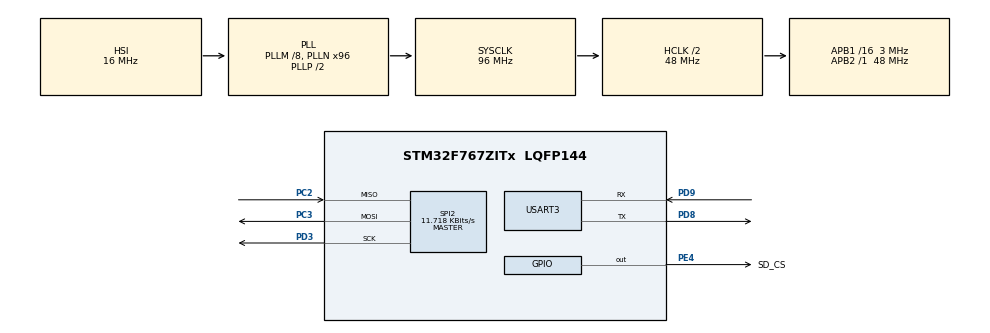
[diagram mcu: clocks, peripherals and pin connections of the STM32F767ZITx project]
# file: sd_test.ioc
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FATFS._FS_NORTC=0
FATFS._MAX_SS=512
FATFS._USE_LFN=0
Mcu.Family=STM32F7
Mcu.Name=STM32F767ZITx
Mcu.Package=LQFP144
NVIC.PriorityGroup=NVIC_PRIORITYGROUP_4
PA13.Mode=Serial_Wire
PA13.Signal=SYS_JTMS-SWDIO
PA14.Mode=Serial_Wire
PA14.Signal=SYS_JTCK-SWCLK
PC2.Mode=Full_Duplex_Master
PC2.Signal=SPI2_MISO
PC3.Mode=Full_Duplex_Master
PC3.Signal=SPI2_MOSI
PD3.Mode=Full_Duplex_Master
PD3.Signal=SPI2_SCK
PD8.Mode=Asynchronous
PD8.Signal=USART3_TX
PD9.Mode=Asynchronous
PD9.Signal=USART3_RX
PE4.GPIO_Label=SD_CS
PE4.GPIO_Speed=GPIO_SPEED_FREQ_VERY_HIGH
PE4.Signal=GPIO_Output
ProjectManager.HeapSize=0x200
ProjectManager.StackSize=0x400
ProjectManager.TargetToolchain=MDK-ARM V5
RCC.48MHZClocksFreq_Value=24000000
RCC.AHBCLKDivider=RCC_SYSCLK_DIV2
RCC.AHBFreq_Value=48000000
RCC.APB1CLKDivider=RCC_HCLK_DIV16
RCC.APB1Freq_Value=3000000
RCC.APB1TimFreq_Value=6000000
RCC.APB2Freq_Value=48000000
RCC.APB2TimFreq_Value=48000000
RCC.CortexFreq_Value=48000000
RCC.HCLKFreq_Value=48000000
RCC.HSE_VALUE=16000000
RCC.HSI_VALUE=16000000
RCC.LSE_VALUE=32768
RCC.PLLM=8
RCC.PLLMUL=RCC_PLL_MUL9
RCC.PLLN=96
RCC.PRESCALERUSB=RCC_USBCLKSOURCE_PLL_DIV1_5
RCC.SYSCLKFreq_VALUE=96000000
RCC.SYSCLKSource=RCC_SYSCLKSOURCE_PLLCLK
RCC.SYSCLKSourceVirtual=RCC_SYSCLKSOURCE_PLLCLK
RCC.USBFreq_Value=96000000
RCC.VCOOutputFreq_Value=192000000
SPI2.BaudRatePrescaler=SPI_BAUDRATEPRESCALER_256
SPI2.CRCCalculation=SPI_CRCCALCULATION_ENABLE
SPI2.CalculateBaudRate=11.718 KBits/s
SPI2.DataSize=SPI_DATASIZE_8BIT
SPI2.Direction=SPI_DIRECTION_2LINES
SPI2.Mode=SPI_MODE_MASTER
SPI2.VirtualType=VM_MASTER
USART3.VirtualMode-Asynchronous=VM_ASYNC
VP_FATFS_VS_Generic.Mode=User_defined
board=NUCLEO-F767ZI

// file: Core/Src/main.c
/* USER CODE BEGIN Header */
/**
  ******************************************************************************
  * @file           : main.c
  * @brief          : Main program body
  ******************************************************************************
  * @attention
  *
  * <h2><center>&copy; Copyright (c) 2019 STMicroelectronics.
  * All rights reserved.</center></h2>
  *
  * This software component is licensed by ST under Ultimate Liberty license
  * SLA0044, the "License"; You may not use this file except in compliance with
  * the License. You may obtain a copy of the License at:
  *                             www.st.com/SLA0044
  *
  ******************************************************************************
  */
/* USER CODE END Header */

#include "main.h"
#include "fatfs.h"
#include "spi.h"
#include "usart.h"
#include "gpio.h"

/* USER CODE BEGIN Includes */
#include <stdio.h>
#include <string.h>
#include "stm32f7xx_hal.h"

/* USER CODE END Includes */

void SystemClock_Config(void);

int main(void)
{

  /* MCU Configuration--------------------------------------------------------*/

  /* Reset of all peripherals, Initializes the Flash interface and the Systick. */
  HAL_Init();

  /* Configure the system clock */
  SystemClock_Config();

  /* Initialize all configured peripherals */
  MX_GPIO_Init();
  MX_SPI2_Init();
  MX_USART3_UART_Init();
  MX_FATFS_Init();
  /* USER CODE BEGIN 2 */

	//Fatfs object
  FATFS FatFs;
  //File object
  FIL fil;

	FRESULT fres;

	printf("Hello world\r\n");

	fres = f_mount(&FatFs, "0:", 1); //1=mount now
		if (fres != FR_OK) {
      printf("f_mount error (%d)\r\n", fres);

    }

		f_mount(NULL, "0:", 0);		//unmount drive

  /* USER CODE END 2 */

  /* Infinite loop */
  while (1)
  {

  }
}

void SystemClock_Config(void)
{
  RCC_OscInitTypeDef RCC_OscInitStruct = {0};
  RCC_ClkInitTypeDef RCC_ClkInitStruct = {0};
  RCC_PeriphCLKInitTypeDef PeriphClkInitStruct = {0};

  /** Configure the main internal regulator output voltage
  */
  __HAL_RCC_PWR_CLK_ENABLE();
  __HAL_PWR_VOLTAGESCALING_CONFIG(PWR_REGULATOR_VOLTAGE_SCALE3);
  /** Initializes the CPU, AHB and APB busses clocks
  */
  RCC_OscInitStruct.OscillatorType = RCC_OSCILLATORTYPE_HSI;
  RCC_OscInitStruct.HSIState = RCC_HSI_ON;
  RCC_OscInitStruct.HSICalibrationValue = RCC_HSICALIBRATION_DEFAULT;
  RCC_OscInitStruct.PLL.PLLState = RCC_PLL_ON;
  RCC_OscInitStruct.PLL.PLLSource = RCC_PLLSOURCE_HSI;
  RCC_OscInitStruct.PLL.PLLM = 8;
  RCC_OscInitStruct.PLL.PLLN = 96;
  RCC_OscInitStruct.PLL.PLLP = RCC_PLLP_DIV2;
  RCC_OscInitStruct.PLL.PLLQ = 2;
  if (HAL_RCC_OscConfig(&RCC_OscInitStruct) != HAL_OK)
  {
    Error_Handler();
  }
  /** Initializes the CPU, AHB and APB busses clocks
  */
  RCC_ClkInitStruct.ClockType = RCC_CLOCKTYPE_HCLK|RCC_CLOCKTYPE_SYSCLK
                              |RCC_CLOCKTYPE_PCLK1|RCC_CLOCKTYPE_PCLK2;
  RCC_ClkInitStruct.SYSCLKSource = RCC_SYSCLKSOURCE_PLLCLK;
  RCC_ClkInitStruct.AHBCLKDivider = RCC_SYSCLK_DIV2;
  RCC_ClkInitStruct.APB1CLKDivider = RCC_HCLK_DIV16;
  RCC_ClkInitStruct.APB2CLKDivider = RCC_HCLK_DIV1;

  if (HAL_RCC_ClockConfig(&RCC_ClkInitStruct, FLASH_LATENCY_1) != HAL_OK)
  {
    Error_Handler();
  }
  PeriphClkInitStruct.PeriphClockSelection = RCC_PERIPHCLK_USART3;
  PeriphClkInitStruct.Usart3ClockSelection = RCC_USART3CLKSOURCE_PCLK1;
  if (HAL_RCCEx_PeriphCLKConfig(&PeriphClkInitStruct) != HAL_OK)
  {
    Error_Handler();
  }
}

void Error_Handler(void)
{
}

/************************ (C) COPYRIGHT STMicroelectronics *****END OF FILE****/
